# NUC126AE_v1 register map
File version: 1.0
NUC126AE_v1 SVD file
Registers are 32-bit, read-write, reset 0x0 unless marked. A register's access mark holds for its fields unless they carry their own. Offsets are from the block's base; lines under a group give offsets from that group; [hi:lo] are bit positions; {n}, {i} and the like mark numbered series; 'fields as' and 'values as' point back to an identical list; <NAME> marks a mode.

## Memory map
0x40004000 WDT size 0xC — WDT Register Map
0x40004100 WWDT size 0x10 — WWDT Register Map
0x40008000 RTC blocks up to offset 0x114 — RTC Register Map
0x40010000 TMR01 blocks up to offset 0x1A8 — TIMER Register Map
0x40020000 I2C0 blocks up to offset 0x50 — I2C Register Map
0x40030000 SPI0 blocks up to offset 0x6C — SPI Register Map
0x40034000 SPI1 blocks up to offset 0x6C — SPI Register Map
0x40040000 PWM0 blocks up to offset 0x350 — PWM Register Map
0x40050000 UART0 size 0x4C — UART Register Map
0x40060000 USBD blocks up to offset 0x580 — USBD Register Map
0x40070000 UUART0 blocks up to offset 0x68 — UUART Register Map
0x40070000 USPI0 blocks up to offset 0x68 — USPI Register Map
0x40070000 UI2C0 blocks up to offset 0x90 — UI2C Register Map
0x40074000 UUART2 blocks up to offset 0x68 — UUART Register Map
0x40074000 USPI2 blocks up to offset 0x68 — USPI Register Map
0x40074000 UI2C2 blocks up to offset 0x90 — UI2C Register Map
0x400D0000 ACMP01 size 0x10 — ACMP Register Map
0x400E0000 ADC blocks up to offset 0x104 — ADC Register Map
0x40110000 TMR23 blocks up to offset 0x1A8 — TIMER Register Map
0x40120000 I2C1 blocks up to offset 0x50 — I2C Register Map
0x40140000 PWM1 blocks up to offset 0x350 — PWM Register Map
0x40150000 UART1 size 0x4C — UART Register Map
0x40154000 UART2 size 0x4C — UART Register Map
0x40170000 UUART1 blocks up to offset 0x68 — UUART Register Map
0x40170000 USPI1 blocks up to offset 0x68 — USPI Register Map
0x40170000 UI2C1 blocks up to offset 0x90 — UI2C Register Map
0x40190000 SC0 blocks up to offset 0x50 — SC Register Map
0x40194000 SC1 blocks up to offset 0x50 — SC Register Map
0x50000000 SYS blocks up to offset 0x118 — SYS Register Map
0x50000200 CLK blocks up to offset 0x80 — CLK Register Map
0x50000300 INT size 0x84 — INT Register Map
0x50004000 GPIO blocks up to offset 0x360 — GPIO Register Map
0x50008000 PDMA blocks up to offset 0x488 — PDMA Register Map
0x5000C000 FMC blocks up to offset 0xC8 — FMC Register Map
0x50010000 EBI blocks up to offset 0x18 — EBI Register Map
0x50014000 HDIV size 0x14 — HDIV Register Map
0x50018000 CRC size 0x10 — CRC Register Map
0xE000E000 SCS blocks up to offset 0xD24 — SYST_NVIC_SCS Register Map

## INT — INT Register Map
Base 0x50000300
0x00 IRQ0_SRC ro reset not defined — IRQ0 (BOD) Interrupt Source Identity
  [3:0] INT_SRC — Interrupt Source. Define the interrupt sources for interrupt event.
0x04 IRQ1_SRC ro reset not defined — IRQ1 (WDT) Interrupt Source Identity
  fields as IRQ0_SRC
0x08 IRQ2_SRC ro reset not defined — IRQ2 (EINT0/2/4) Interrupt Source Identity
  fields as IRQ0_SRC
0x0C IRQ3_SRC ro reset not defined — IRQ3 (EINT1/3/5) Interrupt Source Identity
  fields as IRQ0_SRC
0x10 IRQ4_SRC ro reset not defined — IRQ4 (GPA/B) Interrupt Source Identity
  fields as IRQ0_SRC
0x14 IRQ5_SRC ro reset not defined — IRQ5 (GPC/D/E/F) Interrupt Source Identity
  fields as IRQ0_SRC
0x18 IRQ6_SRC ro reset not defined — IRQ6 (PWM0) Interrupt Source Identity
  fields as IRQ0_SRC
0x1C IRQ7_SRC ro reset not defined — IRQ7 (PWM1) Interrupt Source Identity
  fields as IRQ0_SRC
{0x0+4i} IRQ{i}_SRC ro reset not defined (i=8..11) — IRQ{i} (TMR{i-8}) Interrupt Source Identity
  fields as IRQ0_SRC
0x30 IRQ12_SRC ro reset not defined — IRQ12 (UART0/2) Interrupt Source Identity
  fields as IRQ0_SRC
0x34 IRQ13_SRC ro reset not defined — IRQ13 (UART1) Interrupt Source Identity
  fields as IRQ0_SRC
0x38 IRQ14_SRC ro reset not defined — IRQ14 (SPI0) Interrupt Source Identity
  fields as IRQ0_SRC
0x3C IRQ15_SRC ro reset not defined — IRQ15 (SPI1) Interrupt Source Identity
  fields as IRQ0_SRC
0x40 IRQ16_SRC ro reset not defined — Reserved.
  fields as IRQ0_SRC
0x44 IRQ17_SRC ro reset not defined — Reserved.
  fields as IRQ0_SRC
0x48 IRQ18_SRC ro reset not defined — IRQ18 (I2C0) Interrupt Source Identity
  fields as IRQ0_SRC
0x4C IRQ19_SRC ro reset not defined — IRQ19 (I2C1) Interrupt Source Identity
  fields as IRQ0_SRC
0x50 IRQ20_SRC ro reset not defined — Reserved.
  fields as IRQ0_SRC
0x54 IRQ21_SRC ro reset not defined — Reserved.
  fields as IRQ0_SRC
0x58 IRQ22_SRC ro reset not defined — IRQ22 (USCI0/1/2) Interrupt Source Identity
  fields as IRQ0_SRC
0x5C IRQ23_SRC ro reset not defined — IRQ23 (USBD) Interrupt Source Identity
  fields as IRQ0_SRC
0x60 IRQ24_SRC ro reset not defined — IRQ24 (SC0/1) Interrupt Source Identify
  fields as IRQ0_SRC
0x64 IRQ25_SRC ro reset not defined — IRQ25 (ACMP) Interrupt Source Identity
  fields as IRQ0_SRC
0x68 IRQ26_SRC ro reset not defined — IRQ26 (PDMA) Interrupt Source Identity
  fields as IRQ0_SRC
0x6C IRQ27_SRC ro reset not defined — Reserved.
  fields as IRQ0_SRC
0x70 IRQ28_SRC ro reset not defined — IRQ28 (PWRWU) Interrupt Source Identity
  fields as IRQ0_SRC
0x74 IRQ29_SRC ro reset not defined — IRQ29 (ADC) Interrupt Source Identity
  fields as IRQ0_SRC
0x78 IRQ30_SRC ro reset not defined — IRQ30 (IRC/CLKD) Interrupt Source Identity
  fields as IRQ0_SRC
0x7C IRQ31_SRC ro reset not defined — IRQ31 (RTC) Interrupt Source Identity
  fields as IRQ0_SRC
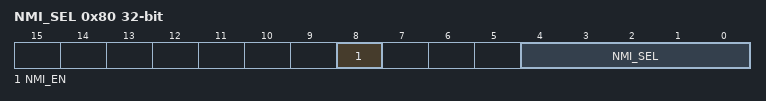
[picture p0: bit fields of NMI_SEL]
0x80 NMI_SEL — NMI Source Interrupt Select Control Register
  [8] NMI_EN — NMI Interrupt Enable Bit (Write Protect). Note: This bit is write protected. Refer to the SYS_REGLCTL register.
    0=NMI interrupt Disabled; 1=NMI interrupt Enabled
  [4:0] NMI_SEL — NMI Interrupt Source Selection. The NMI interrupt to Cortex-M0 can be selected from one of the peripheral interrupt by setting NMI_SEL.
